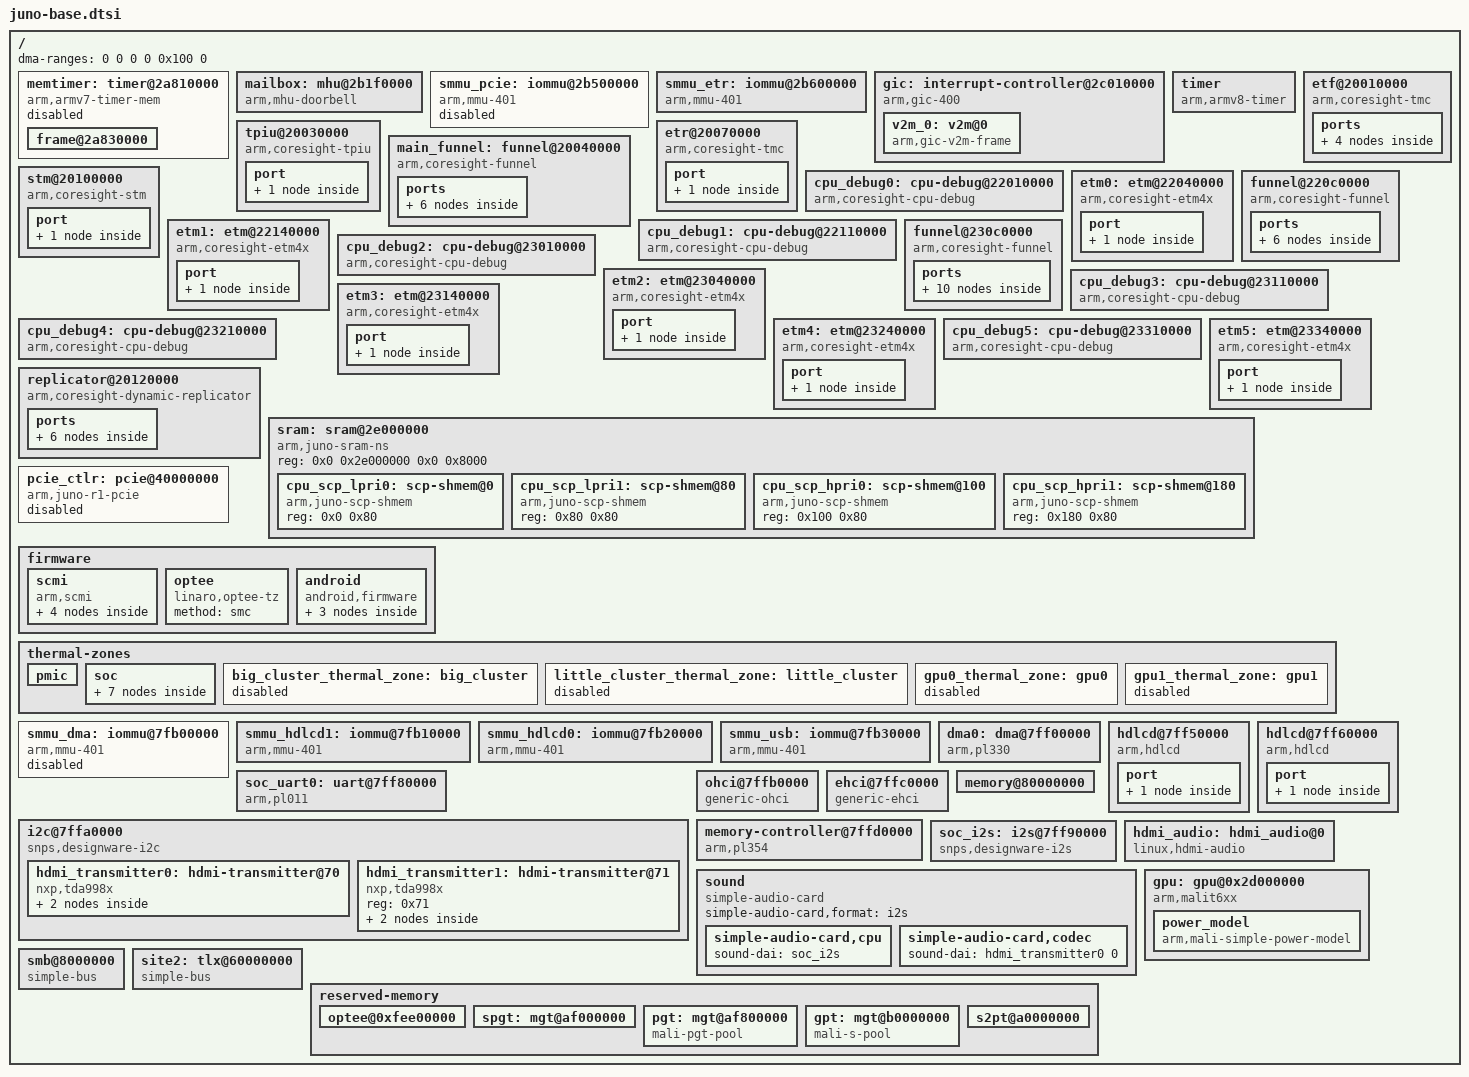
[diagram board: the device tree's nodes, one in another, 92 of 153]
// SPDX-License-Identifier: GPL-2.0
#include "juno-clocks.dtsi"
#include <dt-bindings/display/tda998x.h>

/ {
	/*
	 *  Devices shared by all Juno boards
	 */
	dma-ranges = <0 0 0 0 0x100 0>;

	memtimer: timer@2a810000 {
		compatible = "arm,armv7-timer-mem";
		reg = <0x0 0x2a810000 0x0 0x10000>;
		clock-frequency = <50000000>;
		#address-cells = <2>;
		#size-cells = <2>;
		ranges;
		status = "disabled";
		frame@2a830000 {
			frame-number = <1>;
			interrupts = <0 60 4>;
			reg = <0x0 0x2a830000 0x0 0x10000>;
		};
	};

	mailbox: mhu@2b1f0000 {
		compatible = "arm,mhu-doorbell", "arm,primecell";
		reg = <0x0 0x2b1f0000 0x0 0x1000>;
		interrupts = <GIC_SPI 36 IRQ_TYPE_LEVEL_HIGH>,
			     <GIC_SPI 35 IRQ_TYPE_LEVEL_HIGH>;
		interrupt-names = "mhu_lpri_rx",
				  "mhu_hpri_rx";
		#mbox-cells = <2>;
		mbox-name = "ARM-MHU";
		clocks = <&soc_refclk100mhz>;
		clock-names = "apb_pclk";
	};

	smmu_pcie: iommu@2b500000 {
		compatible = "arm,mmu-401", "arm,smmu-v1";
		reg = <0x0 0x2b500000 0x0 0x10000>;
		interrupts = <GIC_SPI 40 IRQ_TYPE_LEVEL_HIGH>,
			     <GIC_SPI 40 IRQ_TYPE_LEVEL_HIGH>;
		#iommu-cells = <1>;
		#global-interrupts = <1>;
		dma-coherent;
		status = "disabled";
	};

	smmu_etr: iommu@2b600000 {
		compatible = "arm,mmu-401", "arm,smmu-v1";
		reg = <0x0 0x2b600000 0x0 0x10000>;
		interrupts = <GIC_SPI 42 IRQ_TYPE_LEVEL_HIGH>,
			     <GIC_SPI 42 IRQ_TYPE_LEVEL_HIGH>;
		#iommu-cells = <1>;
		#global-interrupts = <1>;
		dma-coherent;
		power-domains = <&scmi_devpd 8>;
	};

	gic: interrupt-controller@2c010000 {
		compatible = "arm,gic-400", "arm,cortex-a15-gic";
		reg = <0x0 0x2c010000 0 0x1000>,
		      <0x0 0x2c02f000 0 0x2000>,
		      <0x0 0x2c04f000 0 0x2000>,
		      <0x0 0x2c06f000 0 0x2000>;
		#address-cells = <2>;
		#interrupt-cells = <3>;
		#size-cells = <2>;
		interrupt-controller;
		interrupts = <GIC_PPI 9 (GIC_CPU_MASK_SIMPLE(6) | IRQ_TYPE_LEVEL_HIGH)>;
		ranges = <0 0 0 0x2c1c0000 0 0x40000>;
		v2m_0: v2m@0 {
			compatible = "arm,gic-v2m-frame";
			msi-controller;
			reg = <0 0 0 0x1000>;
		};
	};

	timer {
		compatible = "arm,armv8-timer";
		interrupts = <GIC_PPI 13 (GIC_CPU_MASK_SIMPLE(6) | IRQ_TYPE_LEVEL_LOW)>,
			     <GIC_PPI 14 (GIC_CPU_MASK_SIMPLE(6) | IRQ_TYPE_LEVEL_LOW)>,
			     <GIC_PPI 11 (GIC_CPU_MASK_SIMPLE(6) | IRQ_TYPE_LEVEL_LOW)>,
			     <GIC_PPI 10 (GIC_CPU_MASK_SIMPLE(6) | IRQ_TYPE_LEVEL_LOW)>;
	};

	/*
	 * Juno TRMs specify the size for these coresight components as 64K.
	 * The actual size is just 4K though 64K is reserved. Access to the
	 * unmapped reserved region results in a DECERR response.
	 */
	etf@20010000 { /* etf0 */
		compatible = "arm,coresight-tmc", "arm,primecell";
		reg = <0 0x20010000 0 0x1000>;

		clocks = <&soc_smc50mhz>;
		clock-names = "apb_pclk";
		power-domains = <&scmi_devpd 8>;
		ports {
			#address-cells = <1>;
			#size-cells = <0>;

			/* input port */
			port@0 {
				reg = <0>;
				etf0_in_port: endpoint {
					slave-mode;
					remote-endpoint = <&main_funnel_out_port>;
				};
			};

			/* output port */
			port@1 {
				reg = <0>;
				etf0_out_port: endpoint {
				};
			};
		};
	};

	tpiu@20030000 {
		compatible = "arm,coresight-tpiu", "arm,primecell";
		reg = <0 0x20030000 0 0x1000>;

		clocks = <&soc_smc50mhz>;
		clock-names = "apb_pclk";
		power-domains = <&scmi_devpd 8>;
		port {
			tpiu_in_port: endpoint {
				slave-mode;
				remote-endpoint = <&replicator_out_port0>;
			};
		};
	};

	/* main funnel on Juno r0, cssys0 funnel on Juno r1/r2 as per TRM*/
	main_funnel: funnel@20040000 {
		compatible = "arm,coresight-funnel", "arm,primecell";
		reg = <0 0x20040000 0 0x1000>;

		clocks = <&soc_smc50mhz>;
		clock-names = "apb_pclk";
		power-domains = <&scmi_devpd 8>;
		ports {
			#address-cells = <1>;
			#size-cells = <0>;

			/* output port */
			port@0 {
				reg = <0>;
				main_funnel_out_port: endpoint {
					remote-endpoint = <&etf0_in_port>;
				};
			};

			/* input ports */
			port@1 {
				reg = <0>;
				main_funnel_in_port0: endpoint {
					slave-mode;
					remote-endpoint = <&cluster0_funnel_out_port>;
				};
			};

			port@2 {
				reg = <1>;
				main_funnel_in_port1: endpoint {
					slave-mode;
					remote-endpoint = <&cluster1_funnel_out_port>;
				};
			};
		};
	};

	etr@20070000 {
		compatible = "arm,coresight-tmc", "arm,primecell";
		reg = <0 0x20070000 0 0x1000>;
		iommus = <&smmu_etr 0>;

		clocks = <&soc_smc50mhz>;
		clock-names = "apb_pclk";
		power-domains = <&scmi_devpd 8>;
		port {
			etr_in_port: endpoint {
				slave-mode;
				remote-endpoint = <&replicator_out_port1>;
			};
		};
	};

	stm@20100000 {
		compatible = "arm,coresight-stm", "arm,primecell";
		reg = <0 0x20100000 0 0x1000>,
		      <0 0x28000000 0 0x1000000>;
		reg-names = "stm-base", "stm-stimulus-base";

		clocks = <&soc_smc50mhz>;
		clock-names = "apb_pclk";
		power-domains = <&scmi_devpd 8>;
		port {
			stm_out_port: endpoint {
			};
		};
	};

	cpu_debug0: cpu-debug@22010000 {
		compatible = "arm,coresight-cpu-debug", "arm,primecell";
		reg = <0x0 0x22010000 0x0 0x1000>;

		clocks = <&soc_smc50mhz>;
		clock-names = "apb_pclk";
		power-domains = <&scmi_devpd 8>;
	};

	etm0: etm@22040000 {
		compatible = "arm,coresight-etm4x", "arm,primecell";
		reg = <0 0x22040000 0 0x1000>;

		clocks = <&soc_smc50mhz>;
		clock-names = "apb_pclk";
		power-domains = <&scmi_devpd 8>;
		port {
			cluster0_etm0_out_port: endpoint {
				remote-endpoint = <&cluster0_funnel_in_port0>;
			};
		};
	};

	funnel@220c0000 { /* cluster0 funnel */
		compatible = "arm,coresight-funnel", "arm,primecell";
		reg = <0 0x220c0000 0 0x1000>;

		clocks = <&soc_smc50mhz>;
		clock-names = "apb_pclk";
		power-domains = <&scmi_devpd 8>;
		ports {
			#address-cells = <1>;
			#size-cells = <0>;

			port@0 {
				reg = <0>;
				cluster0_funnel_out_port: endpoint {
					remote-endpoint = <&main_funnel_in_port0>;
				};
			};

			port@1 {
				reg = <0>;
				cluster0_funnel_in_port0: endpoint {
					slave-mode;
					remote-endpoint = <&cluster0_etm0_out_port>;
				};
			};

			port@2 {
				reg = <1>;
				cluster0_funnel_in_port1: endpoint {
					slave-mode;
					remote-endpoint = <&cluster0_etm1_out_port>;
				};
			};
		};
	};

	cpu_debug1: cpu-debug@22110000 {
		compatible = "arm,coresight-cpu-debug", "arm,primecell";
		reg = <0x0 0x22110000 0x0 0x1000>;

		clocks = <&soc_smc50mhz>;
		clock-names = "apb_pclk";
		power-domains = <&scmi_devpd 8>;
	};

	etm1: etm@22140000 {
		compatible = "arm,coresight-etm4x", "arm,primecell";
		reg = <0 0x22140000 0 0x1000>;

		clocks = <&soc_smc50mhz>;
		clock-names = "apb_pclk";
		power-domains = <&scmi_devpd 8>;
		port {
			cluster0_etm1_out_port: endpoint {
				remote-endpoint = <&cluster0_funnel_in_port1>;
			};
		};
	};

	cpu_debug2: cpu-debug@23010000 {
		compatible = "arm,coresight-cpu-debug", "arm,primecell";
		reg = <0x0 0x23010000 0x0 0x1000>;

		clocks = <&soc_smc50mhz>;
		clock-names = "apb_pclk";
		power-domains = <&scmi_devpd 8>;
	};

	etm2: etm@23040000 {
		compatible = "arm,coresight-etm4x", "arm,primecell";
		reg = <0 0x23040000 0 0x1000>;

		clocks = <&soc_smc50mhz>;
		clock-names = "apb_pclk";
		power-domains = <&scmi_devpd 8>;
		port {
			cluster1_etm0_out_port: endpoint {
				remote-endpoint = <&cluster1_funnel_in_port0>;
			};
		};
	};

	funnel@230c0000 { /* cluster1 funnel */
		compatible = "arm,coresight-funnel", "arm,primecell";
		reg = <0 0x230c0000 0 0x1000>;

		clocks = <&soc_smc50mhz>;
		clock-names = "apb_pclk";
		power-domains = <&scmi_devpd 8>;
		ports {
			#address-cells = <1>;
			#size-cells = <0>;

			port@0 {
				reg = <0>;
				cluster1_funnel_out_port: endpoint {
					remote-endpoint = <&main_funnel_in_port1>;
				};
			};

			port@1 {
				reg = <0>;
				cluster1_funnel_in_port0: endpoint {
					slave-mode;
					remote-endpoint = <&cluster1_etm0_out_port>;
				};
			};

			port@2 {
				reg = <1>;
				cluster1_funnel_in_port1: endpoint {
					slave-mode;
					remote-endpoint = <&cluster1_etm1_out_port>;
				};
			};
			port@3 {
				reg = <2>;
				cluster1_funnel_in_port2: endpoint {
					slave-mode;
					remote-endpoint = <&cluster1_etm2_out_port>;
				};
			};
			port@4 {
				reg = <3>;
				cluster1_funnel_in_port3: endpoint {
					slave-mode;
					remote-endpoint = <&cluster1_etm3_out_port>;
				};
			};
		};
	};

	cpu_debug3: cpu-debug@23110000 {
		compatible = "arm,coresight-cpu-debug", "arm,primecell";
		reg = <0x0 0x23110000 0x0 0x1000>;

		clocks = <&soc_smc50mhz>;
		clock-names = "apb_pclk";
		power-domains = <&scmi_devpd 8>;
	};

	etm3: etm@23140000 {
		compatible = "arm,coresight-etm4x", "arm,primecell";
		reg = <0 0x23140000 0 0x1000>;

		clocks = <&soc_smc50mhz>;
		clock-names = "apb_pclk";
		power-domains = <&scmi_devpd 8>;
		port {
			cluster1_etm1_out_port: endpoint {
				remote-endpoint = <&cluster1_funnel_in_port1>;
			};
		};
	};

	cpu_debug4: cpu-debug@23210000 {
		compatible = "arm,coresight-cpu-debug", "arm,primecell";
		reg = <0x0 0x23210000 0x0 0x1000>;

		clocks = <&soc_smc50mhz>;
		clock-names = "apb_pclk";
		power-domains = <&scmi_devpd 8>;
	};

	etm4: etm@23240000 {
		compatible = "arm,coresight-etm4x", "arm,primecell";
		reg = <0 0x23240000 0 0x1000>;

		clocks = <&soc_smc50mhz>;
		clock-names = "apb_pclk";
		power-domains = <&scmi_devpd 8>;
		port {
			cluster1_etm2_out_port: endpoint {
				remote-endpoint = <&cluster1_funnel_in_port2>;
			};
		};
	};

	cpu_debug5: cpu-debug@23310000 {
		compatible = "arm,coresight-cpu-debug", "arm,primecell";
		reg = <0x0 0x23310000 0x0 0x1000>;

		clocks = <&soc_smc50mhz>;
		clock-names = "apb_pclk";
		power-domains = <&scmi_devpd 8>;
	};

	etm5: etm@23340000 {
		compatible = "arm,coresight-etm4x", "arm,primecell";
		reg = <0 0x23340000 0 0x1000>;

		clocks = <&soc_smc50mhz>;
		clock-names = "apb_pclk";
		power-domains = <&scmi_devpd 8>;
		port {
			cluster1_etm3_out_port: endpoint {
				remote-endpoint = <&cluster1_funnel_in_port3>;
			};
		};
	};

	replicator@20120000 {
		compatible = "arm,coresight-dynamic-replicator", "arm,primecell";
		reg = <0 0x20120000 0 0x1000>;

		clocks = <&soc_smc50mhz>;
		clock-names = "apb_pclk";
		power-domains = <&scmi_devpd 8>;

		ports {
			#address-cells = <1>;
			#size-cells = <0>;

			/* replicator output ports */
			port@0 {
				reg = <0>;
				replicator_out_port0: endpoint {
					remote-endpoint = <&tpiu_in_port>;
				};
			};

			port@1 {
				reg = <1>;
				replicator_out_port1: endpoint {
					remote-endpoint = <&etr_in_port>;
				};
			};

			/* replicator input port */
			port@2 {
				reg = <0>;
				replicator_in_port0: endpoint {
					slave-mode;
				};
			};
		};
	};

	sram: sram@2e000000 {
		compatible = "arm,juno-sram-ns", "mmio-sram";
		reg = <0x0 0x2e000000 0x0 0x8000>;

		#address-cells = <1>;
		#size-cells = <1>;
		ranges = <0 0x0 0x2e000000 0x8000>;

		cpu_scp_lpri0: scp-shmem@0 {
			compatible = "arm,juno-scp-shmem";
			reg = <0x0 0x80>;
		};

		cpu_scp_lpri1: scp-shmem@80 {
			compatible = "arm,juno-scp-shmem";
			reg = <0x80 0x80>;
		};

		cpu_scp_hpri0: scp-shmem@100 {
			compatible = "arm,juno-scp-shmem";
			reg = <0x100 0x80>;
		};

		cpu_scp_hpri1: scp-shmem@180 {
			compatible = "arm,juno-scp-shmem";
			reg = <0x180 0x80>;
		};
	};

	pcie_ctlr: pcie@40000000 {
		compatible = "arm,juno-r1-pcie", "plda,xpressrich3-axi", "pci-host-ecam-generic";
		device_type = "pci";
		reg = <0 0x40000000 0 0x10000000>;	/* ECAM config space */
		bus-range = <0 255>;
		linux,pci-domain = <0>;
		#address-cells = <3>;
		#size-cells = <2>;
		dma-coherent;
		ranges = <0x01000000 0x00 0x00000000 0x00 0x5f800000 0x0 0x00800000>,
			 <0x02000000 0x00 0x50000000 0x00 0x50000000 0x0 0x08000000>,
			 <0x42000000 0x40 0x00000000 0x40 0x00000000 0x1 0x00000000>;
		#interrupt-cells = <1>;
		interrupt-map-mask = <0 0 0 7>;
		interrupt-map = <0 0 0 1 &gic 0 0 0 136 4>,
				<0 0 0 2 &gic 0 0 0 137 4>,
				<0 0 0 3 &gic 0 0 0 138 4>,
				<0 0 0 4 &gic 0 0 0 139 4>;
		msi-parent = <&v2m_0>;
		status = "disabled";
		iommu-map-mask = <0x0>;	/* RC has no means to output PCI RID */
		iommu-map = <0x0 &smmu_pcie 0x0 0x1>;
	};

	firmware {
		scmi {
			compatible = "arm,scmi";
			mbox-names = "tx", "rx";
			mboxes = <&mailbox 0 0 &mailbox 0 1>;
			shmem = <&cpu_scp_lpri0 &cpu_scp_lpri1>;
			#address-cells = <1>;
			#size-cells = <0>;

			scmi_devpd: protocol@11 {
				reg = <0x11>;
				#power-domain-cells = <1>;
			};

			scmi_dvfs: protocol@13 {
				reg = <0x13>;
				#clock-cells = <1>;
				mbox-names = "tx", "rx";
				mboxes = <&mailbox 1 0 &mailbox 1 1>;
				shmem = <&cpu_scp_hpri0 &cpu_scp_hpri1>;
			};

			scmi_clk: protocol@14 {
				reg = <0x14>;
				#clock-cells = <1>;
			};

			scmi_sensors0: protocol@15 {
				reg = <0x15>;
				#thermal-sensor-cells = <1>;
			};
		};
	};

	thermal-zones {
		pmic {
			polling-delay = <1000>;
			polling-delay-passive = <100>;
			thermal-sensors = <&scmi_sensors0 0>;
		};

		soc {
			polling-delay = <1000>;
			polling-delay-passive = <100>;
			sustainable-power = <2500>;
			thermal-sensors = <&scmi_sensors0 3>;

			trips {
				threshold: threshold {
					temperature = <55000>;
					hysteresis = <1000>;
					type = "passive";
				};
				target: target {
					temperature = <65000>;
					hysteresis = <1000>;
					type = "passive";
				};
			};

			cooling-maps {
				map0 {
					trip = <&target>;
					cooling-device = <&A53_0 THERMAL_NO_LIMIT THERMAL_NO_LIMIT>;
					contribution = <2048>;
				};
				big_cluster_cooling_map: map1 {
					trip = <&target>;
					contribution = <1024>;
				};
				map2 {
					trip = <&target>;
					cooling-device = <&gpu THERMAL_NO_LIMIT THERMAL_NO_LIMIT>;
					contribution = <1024>;
				};
			};
		};

		big_cluster_thermal_zone: big_cluster {
			polling-delay = <1000>;
			polling-delay-passive = <100>;
			thermal-sensors = <&scmi_sensors0 21>;
			status = "disabled";
		};

		little_cluster_thermal_zone: little_cluster {
			polling-delay = <1000>;
			polling-delay-passive = <100>;
			thermal-sensors = <&scmi_sensors0 22>;
			status = "disabled";
		};

		gpu0_thermal_zone: gpu0 {
			polling-delay = <1000>;
			polling-delay-passive = <100>;
			thermal-sensors = <&scmi_sensors0 23>;
			status = "disabled";
		};

		gpu1_thermal_zone: gpu1 {
			polling-delay = <1000>;
			polling-delay-passive = <100>;
			thermal-sensors = <&scmi_sensors0 24>;
			status = "disabled";
		};
	};

	smmu_dma: iommu@7fb00000 {
		compatible = "arm,mmu-401", "arm,smmu-v1";
		reg = <0x0 0x7fb00000 0x0 0x10000>;
		interrupts = <GIC_SPI 95 IRQ_TYPE_LEVEL_HIGH>,
			     <GIC_SPI 95 IRQ_TYPE_LEVEL_HIGH>;
		#iommu-cells = <1>;
		#global-interrupts = <1>;
		dma-coherent;
		status = "disabled";
	};

	smmu_hdlcd1: iommu@7fb10000 {
		compatible = "arm,mmu-401", "arm,smmu-v1";
		reg = <0x0 0x7fb10000 0x0 0x10000>;
		interrupts = <GIC_SPI 99 IRQ_TYPE_LEVEL_HIGH>,
			     <GIC_SPI 99 IRQ_TYPE_LEVEL_HIGH>;
		#iommu-cells = <1>;
		#global-interrupts = <1>;
	};

	smmu_hdlcd0: iommu@7fb20000 {
		compatible = "arm,mmu-401", "arm,smmu-v1";
		reg = <0x0 0x7fb20000 0x0 0x10000>;
		interrupts = <GIC_SPI 97 IRQ_TYPE_LEVEL_HIGH>,
			     <GIC_SPI 97 IRQ_TYPE_LEVEL_HIGH>;
		#iommu-cells = <1>;
		#global-interrupts = <1>;
	};

	smmu_usb: iommu@7fb30000 {
		compatible = "arm,mmu-401", "arm,smmu-v1";
		reg = <0x0 0x7fb30000 0x0 0x10000>;
		interrupts = <GIC_SPI 101 IRQ_TYPE_LEVEL_HIGH>,
			     <GIC_SPI 101 IRQ_TYPE_LEVEL_HIGH>;
		#iommu-cells = <1>;
		#global-interrupts = <1>;
		dma-coherent;
	};

	dma0: dma@7ff00000 {
		compatible = "arm,pl330", "arm,primecell";
		reg = <0x0 0x7ff00000 0 0x1000>;
		#dma-cells = <1>;
		#dma-channels = <8>;
		#dma-requests = <32>;
		interrupts = <GIC_SPI 88 IRQ_TYPE_LEVEL_HIGH>,
			     <GIC_SPI 89 IRQ_TYPE_LEVEL_HIGH>,
			     <GIC_SPI 90 IRQ_TYPE_LEVEL_HIGH>,
			     <GIC_SPI 91 IRQ_TYPE_LEVEL_HIGH>,
			     <GIC_SPI 92 IRQ_TYPE_LEVEL_HIGH>,
			     <GIC_SPI 108 IRQ_TYPE_LEVEL_HIGH>,
			     <GIC_SPI 109 IRQ_TYPE_LEVEL_HIGH>,
			     <GIC_SPI 110 IRQ_TYPE_LEVEL_HIGH>,
			     <GIC_SPI 111 IRQ_TYPE_LEVEL_HIGH>;
		iommus = <&smmu_dma 0>,
			 <&smmu_dma 1>,
			 <&smmu_dma 2>,
			 <&smmu_dma 3>,
			 <&smmu_dma 4>,
			 <&smmu_dma 5>,
			 <&smmu_dma 6>,
			 <&smmu_dma 7>,
			 <&smmu_dma 8>;
		clocks = <&soc_faxiclk>;
		clock-names = "apb_pclk";
	};

	hdlcd@7ff50000 {
		compatible = "arm,hdlcd";
		reg = <0 0x7ff50000 0 0x1000>;
		interrupts = <GIC_SPI 93 IRQ_TYPE_LEVEL_HIGH>;
		iommus = <&smmu_hdlcd1 0>;
		clocks = <&scmi_clk 3>;
		clock-names = "pxlclk";

		port {
			hdlcd1_output: hdlcd1-endpoint {
				remote-endpoint = <&tda998x_1_input>;
			};
		};
	};

	hdlcd@7ff60000 {
		compatible = "arm,hdlcd";
		reg = <0 0x7ff60000 0 0x1000>;
		interrupts = <GIC_SPI 85 IRQ_TYPE_LEVEL_HIGH>;
		iommus = <&smmu_hdlcd0 0>;
		clocks = <&scmi_clk 3>;
		clock-names = "pxlclk";

		port {
			hdlcd0_output: hdlcd0-endpoint {
				remote-endpoint = <&tda998x_0_input>;
			};
		};
	};

	soc_uart0: uart@7ff80000 {
		compatible = "arm,pl011", "arm,primecell";
		reg = <0x0 0x7ff80000 0x0 0x1000>;
		interrupts = <GIC_SPI 83 IRQ_TYPE_LEVEL_HIGH>;
		clocks = <&soc_uartclk>, <&soc_refclk100mhz>;
		clock-names = "uartclk", "apb_pclk";
	};

	i2c@7ffa0000 {
		compatible = "snps,designware-i2c";
		reg = <0x0 0x7ffa0000 0x0 0x1000>;
		#address-cells = <1>;
		#size-cells = <0>;
		interrupts = <GIC_SPI 104 IRQ_TYPE_LEVEL_HIGH>;
		clock-frequency = <400000>;
		i2c-sda-hold-time-ns = <500>;
		clocks = <&soc_smc50mhz>;

		hdmi_transmitter0: hdmi-transmitter@70 {
			compatible = "nxp,tda998x";
			reg = <0x70>;
			#sound-dai-cells = <1>;
			audio-ports = <TDA998x_I2S 0x03
					TDA998x_SPDIF 0x04>;
			port {
				tda998x_0_input: tda998x-0-endpoint {
					remote-endpoint = <&hdlcd0_output>;
				};
			};
		};

		hdmi_transmitter1: hdmi-transmitter@71 {
			compatible = "nxp,tda998x";
			reg = <0x71>;
			port {
				tda998x_1_input: tda998x-1-endpoint {
					remote-endpoint = <&hdlcd1_output>;
				};
			};
		};
	};

	ohci@7ffb0000 {
		compatible = "generic-ohci";
		reg = <0x0 0x7ffb0000 0x0 0x10000>;
		interrupts = <GIC_SPI 116 IRQ_TYPE_LEVEL_HIGH>;
		iommus = <&smmu_usb 0>;
		clocks = <&soc_usb48mhz>;
	};

	ehci@7ffc0000 {
		compatible = "generic-ehci";
		reg = <0x0 0x7ffc0000 0x0 0x10000>;
		interrupts = <GIC_SPI 117 IRQ_TYPE_LEVEL_HIGH>;
		iommus = <&smmu_usb 0>;
		clocks = <&soc_usb48mhz>;
	};

	memory-controller@7ffd0000 {
		compatible = "arm,pl354", "arm,primecell";
		reg = <0 0x7ffd0000 0 0x1000>;
		interrupts = <GIC_SPI 86 IRQ_TYPE_LEVEL_HIGH>,
			     <GIC_SPI 87 IRQ_TYPE_LEVEL_HIGH>;
		clocks = <&soc_smc50mhz>;
		clock-names = "apb_pclk";
	};

	memory@80000000 {
		device_type = "memory";
		/* last 16MB of the first memory area is reserved for secure world use by firmware */
		reg = <0x00000000 0x80000000 0x0 0x7f000000>,
		      <0x00000008 0x80000000 0x1 0x80000000>;
	};

	soc_i2s: i2s@7ff90000 {
		compatible = "snps,designware-i2s";
		reg = <0x0 0x7ff90000 0x0 0x1000>;
		clocks = <&scmi_clk 5>, <&soc_refclk100mhz>;
		clock-names = "i2sclk", "apb_pclk";
		#sound-dai-cells = <0>;
		dmas = <&dma0 5>;
		dma-names = "tx";
	};

	hdmi_audio: hdmi_audio@0 {
		compatible = "linux,hdmi-audio";
		#sound-dai-cells = <0>;
		status = "okay";
	};

	sound {
		compatible = "simple-audio-card";

		simple-audio-card,format = "i2s";

		simple-audio-card,cpu {
			sound-dai = <&soc_i2s>;
		};

		simple-audio-card,codec {
			sound-dai = <&hdmi_transmitter0 0>;
		};
	};

	gpu: gpu@0x2d000000 {
		compatible = "arm,malit6xx", "arm,mali-midgard";
        memory-region = <&gpt>;
		#cooling-cells = <2>; /* min followed by max */
		reg = <0x0 0x2d000000 0x0 0x4000>;
		interrupts = <0 33 4>, <0 34 4>, <0 32 4>;
		interrupt-names = "JOB", "MMU", "GPU";
		clocks = <&scmi_dvfs 2>;
		power-domains = <&scmi_devpd 9>;
		power_model {
			compatible = "arm,mali-simple-power-model";
			static-coefficient = <976563>;
			dynamic-coefficient = <4688>;
			ts = <20000 2000 (-20) 2>;
			/*
			 * We can't have a proper GPU thermal zone because Juno
			 * r1 & r2 have two sensors which Linux doesn't support
			 * yet, and for r0 there isn't a separate sensor.
			 *
			 * We also can't create a GPU thermal zone that reuses
			 * the SoC sensor because of another limitation in Linux
			 * code that prevents sensors being used for more that
			 * one zone.
			 *
			 * Warning for the future: Mali contains very dubious
			 * code for setting up OPPs which does a global search
			 * of device-tree for a node called "gpu" and expects
			 * this to be the Mali device. So if we do the natural
			 * thing for a GPU thermal zone and call that node "gpu"
			 * then Mali OPP code will go horribly wrong. We should
			 * therefore call it something different or fix Mali
			 * code to not be so lame.
			 *
			 * With all the above in mind, we will assign here the
			 * GPU to the to the SoC thermal zone and hope that
			 * there's no recursive deadlocks that can occur. E.g.
			 * SoC cooling triggers Mali devfreq cooling and because
			 * that is in the SoC thermal zone it tries to
			 * recursively trigger cooling on the SoC zone.
			 * (This doesn't appear to happen).
			 */
			thermal-zone = "soc";
		};
	};

	smb@8000000 {
		compatible = "simple-bus";
		#address-cells = <2>;
		#size-cells = <1>;
		ranges = <0 0 0 0x08000000 0x04000000>,
			 <1 0 0 0x14000000 0x04000000>,
			 <2 0 0 0x18000000 0x04000000>,
			 <3 0 0 0x1c000000 0x04000000>,
			 <4 0 0 0x0c000000 0x04000000>,
			 <5 0 0 0x10000000 0x04000000>;

		#interrupt-cells = <1>;
		interrupt-map-mask = <0 0 15>;
		interrupt-map = <0 0  0 &gic 0 0 0  68 IRQ_TYPE_LEVEL_HIGH>,
				<0 0  1 &gic 0 0 0  69 IRQ_TYPE_LEVEL_HIGH>,
				<0 0  2 &gic 0 0 0  70 IRQ_TYPE_LEVEL_HIGH>,
				<0 0  3 &gic 0 0 0 160 IRQ_TYPE_LEVEL_HIGH>,
				<0 0  4 &gic 0 0 0 161 IRQ_TYPE_LEVEL_HIGH>,
				<0 0  5 &gic 0 0 0 162 IRQ_TYPE_LEVEL_HIGH>,
				<0 0  6 &gic 0 0 0 163 IRQ_TYPE_LEVEL_HIGH>,
				<0 0  7 &gic 0 0 0 164 IRQ_TYPE_LEVEL_HIGH>,
				<0 0  8 &gic 0 0 0 165 IRQ_TYPE_LEVEL_HIGH>,
				<0 0  9 &gic 0 0 0 166 IRQ_TYPE_LEVEL_HIGH>,
				<0 0 10 &gic 0 0 0 167 IRQ_TYPE_LEVEL_HIGH>,
				<0 0 11 &gic 0 0 0 168 IRQ_TYPE_LEVEL_HIGH>,
				<0 0 12 &gic 0 0 0 169 IRQ_TYPE_LEVEL_HIGH>;

		/include/ "juno-motherboard.dtsi"
	};

	site2: tlx@60000000 {
		compatible = "simple-bus";
		#address-cells = <1>;
		#size-cells = <1>;
		ranges = <0 0 0x60000000 0x10000000>;
		#interrupt-cells = <1>;
		interrupt-map-mask = <0 0>;
		interrupt-map = <0 0 &gic 0 0 0 168 IRQ_TYPE_LEVEL_HIGH>;
	};

	firmware {
		optee {
			compatible = "linaro,optee-tz";
			method = "smc";
		};
		android {
			compatible = "android,firmware";
			fstab {
				compatible = "android,fstab";
				system {
					compatible = "android,system";
					dev = "/dev/block/platform/7ffc0000.ehci/by-name/system" ;
					type = "ext4";
					mnt_flags = "ro,barrier=1,inode_readahead_blks=8" ;
					fsmgr_flags = "wait";
				};
				vendor {
					compatible = "android,vendor";
					dev = "/dev/block/platform/7ffc0000.ehci/by-name/vendor" ;
					type = "ext4";
					mnt_flags = "ro,barrier=1,inode_readahead_blks=8" ;
					fsmgr_flags = "wait";
				};
			};
		};
	};

	reserved-memory {
		#address-cells = <2>;
		#size-cells = <2>;
		ranges;

		/* Shared memory between secure and non-secure world */
		optee@0xfee00000 {
			reg = <0x00000000 0xfee00000 0 0x00200000>;
			no-map;
		};

		spgt:mgt@af000000 { // reserved for bitmap to indicate the usabale memory in GPU
			reg = <0x0 0xaf000000 0x0 0x800000>;
			no-map;
		};
		pgt:mgt@af800000 { // reserved for GPU page table
			compatible = "mali-pgt-pool";
			reusable;
			reg = <0x0 0xaf800000 0x0 0x800000>;
		};
		gpt:mgt@b0000000 { // reserved for secure GPU tasks
			compatible = "mali-s-pool";
			reusable;
			reg = <0x0 0xb0000000 0x0 0x10000000>;
		};
		s2pt@a0000000{ // reserved for S2 page table
			reg = <0x0 0xa0000000 0 0x00400000>;
			no-map;
		};
	};
};
